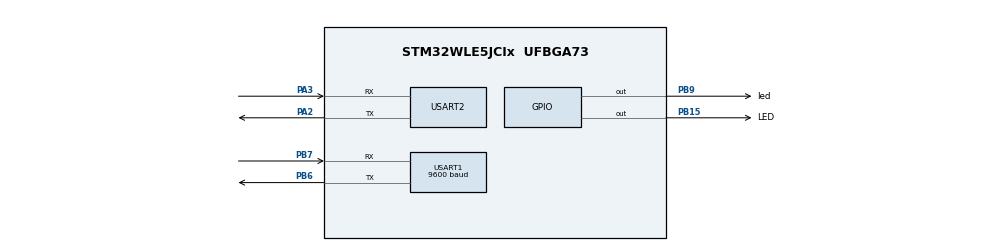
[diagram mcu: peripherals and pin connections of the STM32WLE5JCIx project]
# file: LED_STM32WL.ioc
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Mcu.Family=STM32WL
Mcu.Name=STM32WLE5JCIx
Mcu.Package=UFBGA73
NVIC.PriorityGroup=NVIC_PRIORITYGROUP_4
NVIC.USART1_IRQn=true\:0\:0\:false\:false\:true\:true\:true\:true
PA2.Mode=Asynchronous
PA2.Signal=USART2_TX
PA3.Mode=Asynchronous
PA3.Signal=USART2_RX
PB15.GPIO_Label=LED
PB15.Signal=GPIO_Output
PB6.Mode=Asynchronous
PB6.Signal=USART1_TX
PB7.Mode=Asynchronous
PB7.Signal=USART1_RX
PB9.GPIO_Label=led
PB9.Signal=GPIO_Output
ProjectManager.HeapSize=0x200
ProjectManager.StackSize=0x400
ProjectManager.TargetToolchain=STM32CubeIDE
RCC.HSE_VALUE=8000000
RCC.HSI_VALUE=16000000
RCC.LSE_VALUE=32768
RCC.VCOOutputFreq_Value=32000000
USART1.BaudRate=9600
USART1.VirtualMode-Asynchronous=VM_ASYNC
USART2.VirtualMode-Asynchronous=VM_ASYNC
board=custom

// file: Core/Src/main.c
/* USER CODE BEGIN Header */
/**
  ******************************************************************************
  * @file           : main.c
  * @brief          : Main program body
  ******************************************************************************
  * @attention
  *
  * Copyright (c) 2026 STMicroelectronics.
  * All rights reserved.
  *
  * This software is licensed under terms that can be found in the LICENSE file
  * in the root directory of this software component.
  * If no LICENSE file comes with this software, it is provided AS-IS.
  *
  ******************************************************************************
  */
/* USER CODE END Header */
#include "main.h"
#include <string.h>

UART_HandleTypeDef huart1;
UART_HandleTypeDef huart2;

void SystemClock_Config(void);
static void MX_GPIO_Init(void);
static void MX_USART2_UART_Init(void);
static void MX_USART1_UART_Init(void);

int main(void)
{

  /* MCU Configuration--------------------------------------------------------*/

  /* Reset of all peripherals, Initializes the Flash interface and the Systick. */
  HAL_Init();

  /* Configure the system clock */
  SystemClock_Config();

  /* Initialize all configured peripherals */
  MX_GPIO_Init();
  MX_USART2_UART_Init();
  MX_USART1_UART_Init();
  /* USER CODE BEGIN 2 */
  char mensaje_prueba[] = "¡Hola! Si lees esto, esta es la UART correcta.\r\n";
  /* USER CODE END 2 */

  /* Infinite loop */
  /* USER CODE BEGIN WHILE */
  while (1)
  {
	  HAL_UART_Transmit(&huart2, (uint8_t*)mensaje_prueba, strlen(mensaje_prueba), HAL_MAX_DELAY);
	  HAL_GPIO_TogglePin(GPIOB, GPIO_PIN_15);

	      // Esperamos 1 segundo (1000 milisegundos) antes de volver a enviar
	  HAL_Delay(1000);
    /* USER CODE END WHILE */

  }
}

void SystemClock_Config(void)
{
  RCC_OscInitTypeDef RCC_OscInitStruct = {0};
  RCC_ClkInitTypeDef RCC_ClkInitStruct = {0};

  /** Configure the main internal regulator output voltage
  */
  __HAL_PWR_VOLTAGESCALING_CONFIG(PWR_REGULATOR_VOLTAGE_SCALE2);

  /** Initializes the CPU, AHB and APB buses clocks
  */
  RCC_OscInitStruct.OscillatorType = RCC_OSCILLATORTYPE_MSI;
  RCC_OscInitStruct.MSIState = RCC_MSI_ON;
  RCC_OscInitStruct.MSICalibrationValue = RCC_MSICALIBRATION_DEFAULT;
  RCC_OscInitStruct.MSIClockRange = RCC_MSIRANGE_6;
  RCC_OscInitStruct.PLL.PLLState = RCC_PLL_NONE;
  if (HAL_RCC_OscConfig(&RCC_OscInitStruct) != HAL_OK)
  {
    Error_Handler();
  }

  /** Configure the SYSCLKSource, HCLK, PCLK1 and PCLK2 clocks dividers
  */
  RCC_ClkInitStruct.ClockType = RCC_CLOCKTYPE_HCLK3|RCC_CLOCKTYPE_HCLK
                              |RCC_CLOCKTYPE_SYSCLK|RCC_CLOCKTYPE_PCLK1
                              |RCC_CLOCKTYPE_PCLK2;
  RCC_ClkInitStruct.SYSCLKSource = RCC_SYSCLKSOURCE_MSI;
  RCC_ClkInitStruct.AHBCLKDivider = RCC_SYSCLK_DIV1;
  RCC_ClkInitStruct.APB1CLKDivider = RCC_HCLK_DIV1;
  RCC_ClkInitStruct.APB2CLKDivider = RCC_HCLK_DIV1;
  RCC_ClkInitStruct.AHBCLK3Divider = RCC_SYSCLK_DIV1;

  if (HAL_RCC_ClockConfig(&RCC_ClkInitStruct, FLASH_LATENCY_0) != HAL_OK)
  {
    Error_Handler();
  }
}

static void MX_USART1_UART_Init(void)
{

  huart1.Instance = USART1;
  huart1.Init.BaudRate = 9600;
  huart1.Init.WordLength = UART_WORDLENGTH_8B;
  huart1.Init.StopBits = UART_STOPBITS_1;
  huart1.Init.Parity = UART_PARITY_NONE;
  huart1.Init.Mode = UART_MODE_TX_RX;
  huart1.Init.HwFlowCtl = UART_HWCONTROL_NONE;
  huart1.Init.OverSampling = UART_OVERSAMPLING_16;
  huart1.Init.OneBitSampling = UART_ONE_BIT_SAMPLE_DISABLE;
  huart1.Init.ClockPrescaler = UART_PRESCALER_DIV1;
  huart1.AdvancedInit.AdvFeatureInit = UART_ADVFEATURE_NO_INIT;
  if (HAL_UART_Init(&huart1) != HAL_OK)
  {
    Error_Handler();
  }
  if (HAL_UARTEx_SetTxFifoThreshold(&huart1, UART_TXFIFO_THRESHOLD_1_8) != HAL_OK)
  {
    Error_Handler();
  }
  if (HAL_UARTEx_SetRxFifoThreshold(&huart1, UART_RXFIFO_THRESHOLD_1_8) != HAL_OK)
  {
    Error_Handler();
  }
  if (HAL_UARTEx_DisableFifoMode(&huart1) != HAL_OK)
  {
    Error_Handler();
  }

}

static void MX_USART2_UART_Init(void)
{

  huart2.Instance = USART2;
  huart2.Init.BaudRate = 115200;
  huart2.Init.WordLength = UART_WORDLENGTH_8B;
  huart2.Init.StopBits = UART_STOPBITS_1;
  huart2.Init.Parity = UART_PARITY_NONE;
  huart2.Init.Mode = UART_MODE_TX_RX;
  huart2.Init.HwFlowCtl = UART_HWCONTROL_NONE;
  huart2.Init.OverSampling = UART_OVERSAMPLING_16;
  huart2.Init.OneBitSampling = UART_ONE_BIT_SAMPLE_DISABLE;
  huart2.Init.ClockPrescaler = UART_PRESCALER_DIV1;
  huart2.AdvancedInit.AdvFeatureInit = UART_ADVFEATURE_NO_INIT;
  if (HAL_UART_Init(&huart2) != HAL_OK)
  {
    Error_Handler();
  }
  if (HAL_UARTEx_SetTxFifoThreshold(&huart2, UART_TXFIFO_THRESHOLD_1_8) != HAL_OK)
  {
    Error_Handler();
  }
  if (HAL_UARTEx_SetRxFifoThreshold(&huart2, UART_RXFIFO_THRESHOLD_1_8) != HAL_OK)
  {
    Error_Handler();
  }
  if (HAL_UARTEx_DisableFifoMode(&huart2) != HAL_OK)
  {
    Error_Handler();
  }

}

static void MX_GPIO_Init(void)
{
  GPIO_InitTypeDef GPIO_InitStruct = {0};

  /* GPIO Ports Clock Enable */
  __HAL_RCC_GPIOB_CLK_ENABLE();
  __HAL_RCC_GPIOA_CLK_ENABLE();

  /*Configure GPIO pin Output Level */
  HAL_GPIO_WritePin(GPIOB, LED_Pin|led_Pin, GPIO_PIN_RESET);

  /*Configure GPIO pins : LED_Pin led_Pin */
  GPIO_InitStruct.Pin = LED_Pin|led_Pin;
  GPIO_InitStruct.Mode = GPIO_MODE_OUTPUT_PP;
  GPIO_InitStruct.Pull = GPIO_NOPULL;
  GPIO_InitStruct.Speed = GPIO_SPEED_FREQ_LOW;
  HAL_GPIO_Init(GPIOB, &GPIO_InitStruct);

}

void Error_Handler(void)
{
  __disable_irq();
  while (1)
  {
  }
}
